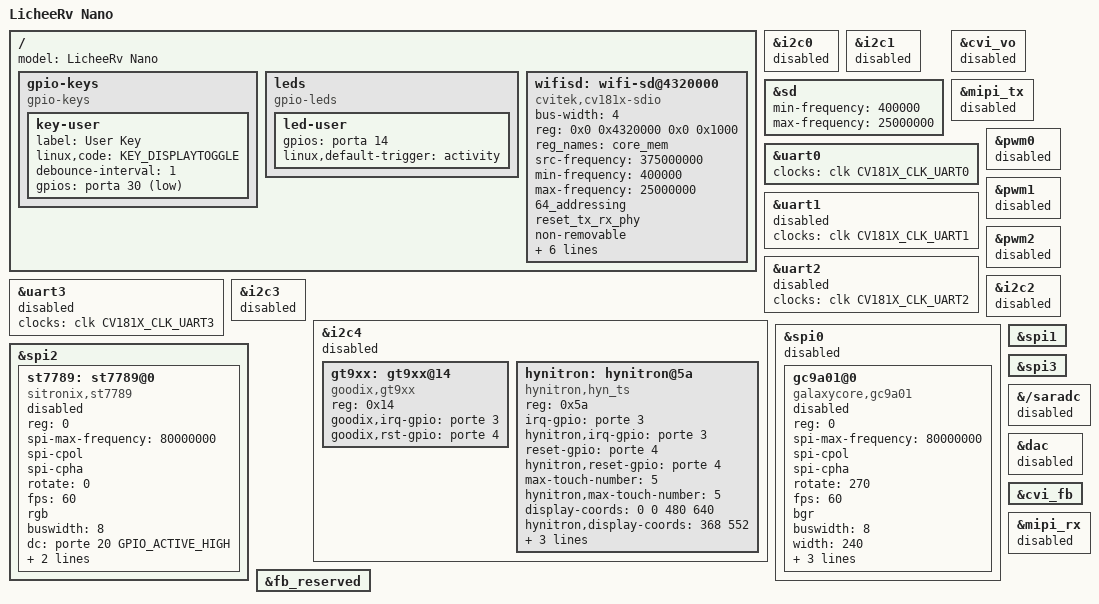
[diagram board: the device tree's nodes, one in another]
/dts-v1/;
#include "soph_base_riscv.dtsi"
#include "soph_asic_qfn.dtsi"
#include "soph_asic_sd.dtsi"
#include "soph_default_memmap.dtsi"

#include <dt-bindings/input/linux-event-codes.h>
#include <dt-bindings/gpio/gpio.h>

&i2c0 {
        status = "disabled";
        /delete-property/ scl-pinmux;
        /delete-property/ sda-pinmux;
        /delete-property/ scl-gpios;
        /delete-property/ sda-gpios;
};

&i2c1 {
        status = "disabled";
        /delete-property/ scl-pinmux;
        /delete-property/ sda-pinmux;
        /delete-property/ scl-gpios;
        /delete-property/ sda-gpios;
};

&sd {
        min-frequency = <400000>; // 400Khz
        //max-frequency = <50000000>; // 50Mhz
        max-frequency = <25000000>; // 25Mhz
        //max-frequency = <10000000>; // 10Mhz
        //max-frequency = <5000000>; // 5Mhz
};

&cvi_vo {
#ifndef __UBOOT__
	status = "disabled";
	/delete-property/ reset-gpio;
	/delete-property/ pwm-gpio;
#else
	status = "okay";
        reset-gpio = <&porte 0 1>;
        pwm-gpio = <&porte 2 1>;
#endif
        /delete-property/ power-ct-gpio;
};

&mipi_tx {
#ifndef __UBOOT__
	/*
	 * C906L owns the four MIPI_TX data pins as SPI0 for GC9A01.
	 * Linux must never probe MIPI TX or rewrite that pinmux.
	 */
	status = "disabled";
	/delete-property/ reset-gpio;
	/delete-property/ pwm-gpio;
#else
	status = "okay";
        /delete-property/ reset-gpio;
        /delete-property/ pwm-gpio;
#endif
        /delete-property/ power-ct-gpio;
};

&uart0 {
	clocks = <&clk CV181X_CLK_UART0>;
	/delete-property/ clock-frequency;
};

&uart1 {
        clocks = <&clk CV181X_CLK_UART1>;
        /delete-property/ clock-frequency;
        status = "disabled";
};

&uart2 {
        clocks = <&clk CV181X_CLK_UART2>;
        /delete-property/ clock-frequency;
        status = "disabled";
};

&uart3 {
        clocks = <&clk CV181X_CLK_UART3>;
        /delete-property/ clock-frequency;
	status = "disabled";
};

&pwm0 {
        status = "disabled";
};

&pwm1 {
      status = "disabled";
};

&pwm2 {
      status = "disabled";
};

&i2c2 {
        status = "disabled";
        /delete-property/ scl-pinmux;
        /delete-property/ sda-pinmux;
        /delete-property/ scl-gpios;
        /delete-property/ sda-gpios;
};

&i2c3 {
        status = "disabled";
        /delete-property/ scl-pinmux;
        /delete-property/ sda-pinmux;
        /delete-property/ scl-gpios;
        /delete-property/ sda-gpios;
};

/*
 * AirLink assigns I2C4/CST816T exclusively to the C906L firmware.
 * Linux must not probe this controller.
 */
&i2c4 {
        status = "disabled";
        gt9xx: gt9xx@14 {
                compatible = "goodix,gt9xx";
                reg = <0x14>;
                goodix,irq-gpio = <&porte 3 0>;
                goodix,rst-gpio = <&porte 4 0>;
                status = "okay";
        };
        hynitron: hynitron@5a {
                compatible = "hynitron,hyn_ts", "hyn,7xx";
                reg = <0x5a>;
                irq-gpio = <&porte 3 0>;
                hynitron,irq-gpio = <&porte 3 0>;
                reset-gpio = <&porte 4 0>;
                hynitron,reset-gpio = <&porte 4 0>;
                max-touch-number = <5>;
                hynitron,max-touch-number = <5>;
                display-coords = <0 0 480 640>;
                hynitron,display-coords = <368 552>;
                pos-swap = <0>;
                posx-reverse = <1>;
                posy-reverse = <1>;
                status = "okay";
        };
};

/*
 * AirLink assigns SPI0/GC9A01 exclusively to the C906L firmware.
 */
&spi0 {
	status = "disabled";
	/delete-node/ spidev@0;

	gc9a01@0 {
		compatible = "galaxycore,gc9a01";
		reg = <0>;
		status = "disabled";
		spi-max-frequency = <80000000>;
		spi-cpol;
		spi-cpha;
		rotate = <270>;
		fps = <60>;
		bgr;
		buswidth = <8>;
		width = <240>;
		height = <240>;
		reset = <&porta 27 GPIO_ACTIVE_HIGH>;
		dc = <&porta 15 GPIO_ACTIVE_HIGH>;
	};
};

&spi1 {
	status = "okay";
};

&spi2 {
	status = "okay";

        // /delete-node/ spidev@0;
        st7789: st7789@0{
		compatible = "sitronix,st7789";
		reg = <0>;
		status = "disabled";
		spi-max-frequency = <80000000>;
		spi-cpol;
		spi-cpha;
		rotate = <0>;
		fps = <60>;
		rgb;
		buswidth = <8>;
		dc = <&porte 20 GPIO_ACTIVE_HIGH>;
		reset = <&porta 14 GPIO_ACTIVE_LOW>;
		debug = <0>;
	};
};

&spi3 {
	status = "okay";
};

/*
 * AirLink reads ADC1 directly from C906L. Disable the SARADC node by its
 * absolute path because the vendor DTS intentionally does not label it.
 */
&{/saradc} {
        status = "disabled";
};

&dac {
        status = "disabled";
        /delete-property/ mute-gpio-r;
};

&fb_reserved {
        status = "okay";
};

&cvi_fb {
        status = "okay";
};

&mipi_rx {
	status = "disabled";
	/delete-property/ snsr-reset;
};

/ {
        model = "LicheeRv Nano";


        gpio-keys {
                compatible = "gpio-keys";
                key-user {
                        label = "User Key";
                        linux,code = <KEY_DISPLAYTOGGLE>;
                        debounce-interval = <1>;
                        gpios = <&porta 30 1>;
                };
        };

	leds {
		compatible = "gpio-leds";

		led-user {
			gpios = <&porta 14 GPIO_ACTIVE_HIGH>;
			linux,default-trigger = "activity";
		};
	};

	// buggy pwm driver, not working, please use userspace pwm api
	/*
	lcd0_backlight: pwm-backlight@0 {
		compatible = "pwm-backlight";
		pwm-names = "backlight";
		pwms = <&pwm2 2 50000000>; // 20Khz
		brightness-levels = <0 2 4 8 16 32 64 128 255>;
		default-brightness-level = <4>;
	};
	*/

        wifisd:wifi-sd@4320000 {
                compatible = "cvitek,cv181x-sdio";
                bus-width = <4>;
                reg = <0x0 0x4320000 0x0 0x1000>;
                reg_names = "core_mem";
                src-frequency = <375000000>;
                min-frequency = <400000>; // 400Khz
                //max-frequency = <50000000>; // 50Mhz
                //max-frequency = <45000000>; // 45Mhz
                //max-frequency = <40000000>; // 40Mhz
                //max-frequency = <35000000>; // 35Mhz
                //max-frequency = <30000000>; // 30Mhz
                max-frequency = <25000000>; // 25Mhz
                //max-frequency = <20000000>; // 20Mhz
                //max-frequency = <15000000>; // 15Mhz
                //max-frequency = <10000000>; // 10Mhz
                //max-frequency = <5000000>; // 5Mhz
                64_addressing;
                reset_tx_rx_phy;
                non-removable;
                pll_index = <0x7>;
                pll_reg = <0x300207C>;
                no-mmc;
                no-sd;
                status = "okay";
                interrupts = <38 IRQ_TYPE_LEVEL_HIGH>;
                interrupt-parent = <&plic0>;
        };
};
